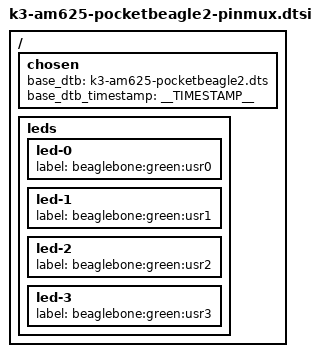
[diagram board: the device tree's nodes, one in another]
// SPDX-License-Identifier: GPL-2.0-only OR MIT
/*
 * https://beagleplay.org/
 *
 * Copyright (C) 2022-2024 Texas Instruments Incorporated - https://www.ti.com/
 * Copyright (C) 2022-2024 Robert Nelson, BeagleBoard.org Foundation
 */

#include <dt-bindings/gpio/gpio.h>

/ {
	chosen {
		base_dtb = "k3-am625-pocketbeagle2.dts";
		base_dtb_timestamp = __TIMESTAMP__;
	};

	leds {
		led-0 {
			label = "beaglebone:green:usr0";
		};

		led-1 {
			label = "beaglebone:green:usr1";
		};

		led-2 {
			label = "beaglebone:green:usr2";
		};

		led-3 {
			label = "beaglebone:green:usr3";
		};
	};
};
